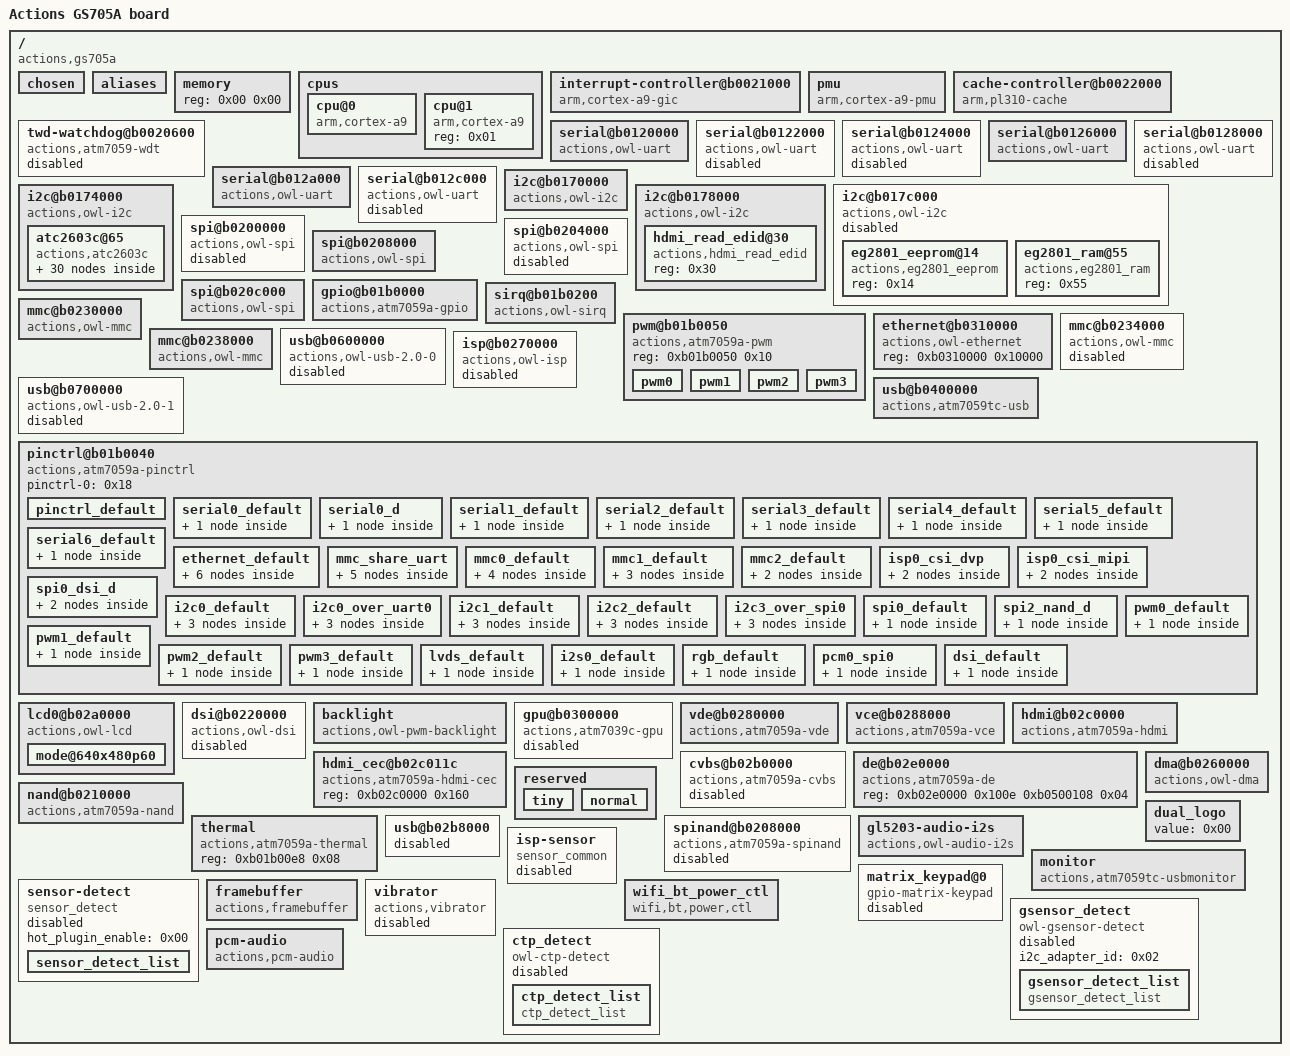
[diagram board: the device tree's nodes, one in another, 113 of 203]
/dts-v1/;

/ {
	#address-cells = < 0x01 >;
	#size-cells = < 0x01 >;
	compatible = "actions,gs705a\0actions,atm7059a";
	interrupt-parent = < 0x01 >;
	model = "Actions GS705A board";

	chosen {
		bootargs = "earlyprintk clk_ignore_unused selinux=0";
	};

	aliases {
		serial0 = "/serial@b0120000";
		serial1 = "/serial@b0122000";
		serial2 = "/serial@b0124000";
		serial3 = "/serial@b0126000";
		serial4 = "/serial@b0128000";
		serial5 = "/serial@b012a000";
		serial6 = "/serial@b012c000";
		i2c0 = "/i2c@b0170000";
		i2c1 = "/i2c@b0174000";
		i2c2 = "/i2c@b0178000";
		i2c3 = "/i2c@b017c000";
		spi0 = "/spi@b0200000";
		spi1 = "/spi@b0204000";
		spi2 = "/spi@b0208000";
		spi3 = "/spi@b020c000";
		dcdc1 = "/i2c@b0174000/atc2603c@65/dcdc1";
		dcdc2 = "/i2c@b0174000/atc2603c@65/dcdc2";
		dcdc3 = "/i2c@b0174000/atc2603c@65/dcdc3";
		dcdc4 = "/i2c@b0174000/atc2603c@65/dcdc4";
		ldo1 = "/i2c@b0174000/atc2603c@65/ldo1";
		ldo2 = "/i2c@b0174000/atc2603c@65/ldo2";
		ldo3 = "/i2c@b0174000/atc2603c@65/ldo3";
		ldo4 = "/i2c@b0174000/atc2603c@65/ldo4";
		ldo5 = "/i2c@b0174000/atc2603c@65/ldo5";
		ldo6 = "/i2c@b0174000/atc2603c@65/ldo6";
		ldo7 = "/i2c@b0174000/atc2603c@65/ldo7";
		ldo8 = "/i2c@b0174000/atc2603c@65/ldo8";
		ldo9 = "/i2c@b0174000/atc2603c@65/ldo9";
		ldo10 = "/i2c@b0174000/atc2603c@65/ldo10";
		ldo11 = "/i2c@b0174000/atc2603c@65/ldo11";
		switch1 = "/i2c@b0174000/atc2603c@65/switch1";
		switch2 = "/i2c@b0174000/atc2603c@65/switch2";
		isp0 = "/isp@b0270000";
		sdboot = "/mmc@b0230000";
		mmc0 = "/mmc@b0230000";
		mmc1 = "/mmc@b0234000";
		mmc2 = "/mmc@b0238000";
		usb0 = "/usb@b0600000";
		usb1 = "/usb@b0700000";
	};

	memory {
		device_type = "memory";
		reg = < 0x00 0x00 >;
	};

	cpus {
		#size-cells = < 0x00 >;
		#address-cells = < 0x01 >;

		cpu@0 {
			device_type = "cpu";
			compatible = "arm,cortex-a9";
			reg = < 0x00 >;
			transition-latency = < 0xee6c >;
			cpuvdd-supply = < 0x02 >;
		};

		cpu@1 {
			device_type = "cpu";
			compatible = "arm,cortex-a9";
			reg = < 0x01 >;
		};
	};

	interrupt-controller@b0021000 {
		compatible = "arm,cortex-a9-gic";
		interrupt-controller;
		#interrupt-cells = < 0x03 >;
		reg = < 0xb0021000 0x1000 0xb0020100 0x100 >;
		linux,phandle = < 0x01 >;
		phandle = < 0x01 >;
	};

	pmu {
		compatible = "arm,cortex-a9-pmu";
		interrupts = < 0x00 0x04 0x04 0x00 0x05 0x04 0x00 0x06 0x04 0x00 0x07 0x04 >;
	};

	cache-controller@b0022000 {
		compatible = "arm,pl310-cache";
		reg = < 0xb0022000 0x1000 >;
		cache-unified;
		cache-level = < 0x02 >;
		interrupts = < 0x00 0x37 0x04 >;
		arm,tag-latency = < 0x03 0x03 0x02 >;
		arm,data-latency = < 0x05 0x03 0x03 >;
	};

	twd-watchdog@b0020600 {
		compatible = "actions,atm7059-wdt";
		reg = < 0xb0020600 0x100 0xb0160000 0x20 >;
		interrupts = < 0x01 0x0e 0xf01 >;
		wd_type = "soft";
		status = "disabled";
	};

	serial@b0120000 {
		compatible = "actions,owl-uart\0actions,owl-uart-irc";
		reg = < 0xb0120000 0x2000 >;
		interrupts = < 0x00 0x1d 0x04 >;
		clock-frequency = < 0x2dc6c00 >;
		pinctrl-names = "default";
		pinctrl-0 = < 0x03 >;
		status = "okay";
	};

	serial@b0122000 {
		compatible = "actions,owl-uart";
		reg = < 0xb0122000 0x2000 >;
		interrupts = < 0x00 0x1e 0x04 >;
		clock-frequency = < 0x2dc6c00 >;
		pinctrl-names = "default";
		pinctrl-0 = < 0x04 >;
		status = "disabled";
	};

	serial@b0124000 {
		compatible = "actions,owl-uart";
		reg = < 0xb0124000 0x2000 >;
		interrupts = < 0x00 0x1f 0x04 >;
		clock-frequency = < 0x2dc6c00 >;
		pinctrl-names = "default";
		pinctrl-0 = < 0x05 >;
		status = "disabled";
	};

	serial@b0126000 {
		compatible = "actions,owl-uart";
		reg = < 0xb0126000 0x2000 >;
		interrupts = < 0x00 0x20 0x04 >;
		clock-frequency = < 0x2dc6c00 >;
		pinctrl-names = "default";
		pinctrl-0 = < 0x06 >;
		status = "okay";
	};

	serial@b0128000 {
		compatible = "actions,owl-uart";
		reg = < 0xb0128000 0x2000 >;
		interrupts = < 0x00 0x21 0x04 >;
		clock-frequency = < 0x2dc6c00 >;
		pinctrl-names = "default";
		pinctrl-0 = < 0x07 >;
		status = "disabled";
	};

	serial@b012a000 {
		compatible = "actions,owl-uart";
		reg = < 0xb012a000 0x2000 >;
		interrupts = < 0x00 0x22 0x04 >;
		clock-frequency = < 0x2dc6c00 >;
		status = "okay";
	};

	serial@b012c000 {
		compatible = "actions,owl-uart";
		reg = < 0xb012c000 0x2000 >;
		interrupts = < 0x00 0x23 0x04 >;
		clock-frequency = < 0x2dc6c00 >;
		pinctrl-names = "default";
		pinctrl-0 = < 0x08 >;
		status = "disabled";
	};

	i2c@b0170000 {
		#address-cells = < 0x01 >;
		#size-cells = < 0x00 >;
		compatible = "actions,owl-i2c";
		reg = < 0xb0170000 0x4000 >;
		interrupts = < 0x00 0x19 0x04 >;
	};

	i2c@b0174000 {
		#address-cells = < 0x01 >;
		#size-cells = < 0x00 >;
		compatible = "actions,owl-i2c";
		reg = < 0xb0174000 0x4000 >;
		interrupts = < 0x00 0x1a 0x04 >;
		i2c_num = < 0x01 >;
		clock-frequency = < 0x61a80 >;
		status = "okay";
		pinctrl-names = "default";
		pinctrl-0 = < 0x09 >;

		atc2603c@65 {
			compatible = "actions,atc2603c";
			reg = < 0x65 >;
			interrupt-parent = < 0x0a >;
			interrupts = < 0x02 0x04 >;
			interrupt-controller;
			#interrupt-cells = < 0x01 >;
			losc_32k_output_enable = < 0x01 >;
			losc_32k_output_voltage = < 0x1f >;

			pm {
				compatible = "actions,atc2603c-pm";
			};

			onoff {
				compatible = "actions,atc2603c-onoff";
			};

			atc260x-pwm {
				compatible = "actions,atc2603c-pwm";
			};

			rtc {
				compatible = "actions,atc2603c-rtc";
			};

			atc260x_gpio {
				compatible = "actions,atc2603c-gpio";
				gpio-controller;
				#gpio-cells = < 0x02 >;
			};

			atc260x_sgpio {
				compatible = "actions,atc2603c-sgpio";
				gpio-controller;
				#gpio-cells = < 0x02 >;
				interrupt-controller;
				#interrupt-cells = < 0x02 >;
				linux,phandle = < 0x1f >;
				phandle = < 0x1f >;
			};

			atc260x-adckeypad {
				keymapsize = < 0x04 >;
				filter_dep = < 0x03 >;
				variance = < 0x0a >;
				poll_interval = < 0x0a >;
				left_adc_val = < 0x00 0x5a 0xaf 0x10e >;
				right_adc_val = < 0x1e 0x78 0xdc 0x140 >;
				key_val = < 0x66 0x8b 0x73 0x72 >;
				adc_channel_name = "AUX0";
				compatible = "actions,atc2603c-adckeypad";
				status = "disabled";
			};

			atc260x-audio {
				compatible = "actions,atc2603c-audio";
				status = "okay";
				pinctrl-names = "default";
				pinctrl-0 = < 0x0b >;
				earphone_detect_gpios = < 0x0c 0x1c 0x00 >;
				speaker_en_gpios = < 0x0c 0x28 0x01 >;
				earphone_output_mode = < 0x01 >;
				mic_num = < 0x01 >;
				mic0_gain = < 0x07 0x07 >;
				speaker_gain = < 0xb4 0xb4 >;
				earphone_gain = < 0xbe 0xbe >;
				mic_mode = < 0x01 >;
				earphone_detect_method = < 0x03 >;
			};

			atc260x-hwmon {
				compatible = "actions,atc2603c-hwmon";
			};

			atc260x-power {
				compatible = "actions,atc2603c-power";
				bl_on_usb_pc_max_charge_current = < 0x64 >;
				bl_off_usb_pc_max_charge_current = < 0x1f4 >;
				bl_on_usb_adp_max_charge_current = < 0x3e8 >;
				bl_off_usb_adp_max_charge_current = < 0x4b0 >;
				bl_on_wall_adp_max_charge_current = < 0x3e8 >;
				bl_off_wall_adp_max_charge_current = < 0x4b0 >;
				bl_on_voltage_diff = < 0x15e >;
				bl_off_voltage_diff = < 0x190 >;
				support_adaptor_type = < 0x01 >;
				usb_adapter_as_ac = < 0x00 >;
				boot_cap_threshold = < 0x03 >;
				ext_dcdc_exist = < 0x00 >;
				pwms = < 0x0d 0x02 0x7a120 0x01 >;
				pwm-names = "ext_moto";
				ext_charger_exist = < 0x00 >;
				charger_led_exist = < 0x01 >;
				inner_charger_led_ctl = < 0x0c 0x16 0x00 >;
				low_power_led_ctl = < 0x0c 0x15 0x01 >;
				work_led_ctl = < 0x0c 0x12 0x01 >;
				myotg_id = < 0x0c 0x6a 0x00 >;
				otg_1_ctl = < 0x0c 0x17 0x00 >;
				otg_2_ctl = < 0x0c 0x5f 0x00 >;
				no_screen = < 0x01 >;
				temp_ctl_enable = < 0x00 >;
				temp_shutdown_low = < 0x3ed >;
				temp_stop_low = < 0x00 >;
				temp_shutdown_high = < 0x32 >;
				temp_stop_high = < 0x2d >;
				temp_diff_restart = < 0x02 >;
			};

			atc260x-cap-gauge {
				compatible = "actions,atc2603c-cap-gauge";
				capacity = < 0x834 >;
				icm_available = < 0x01 >;
				icm_ohm_val = < 0x14 >;
				taper_voltage = < 0x1068 >;
				taper_current = < 0x12c >;
				min_over_chg_protect_voltage = < 0x10b3 >;
				ch_resistor = < 0x78 >;
				disch_resistor = < 0xb4 >;
				terminal_voltage = < 0xd7a >;
				suspend_current = < 0x578 >;
				shutdown_current = < 0x32 >;
				print_switch = < 0x00 >;
				log_switch = < 0x00 >;
				ocv_soc_00 = < 0xd95 0xdce 0xe07 0xe28 0xe35 0xe41 0xe4d 0xe53 0xe59 0xe5d >;
				ocv_soc_10 = < 0xe62 0xe65 0xe6a 0xe6d 0xe74 0xe7a 0xe80 0xe84 0xe8a 0xe90 >;
				ocv_soc_20 = < 0xe94 0xe98 0xe9b 0xea0 0xea3 0xea7 0xeab 0xeae 0xeb1 0xeb5 >;
				ocv_soc_30 = < 0xeb8 0xebb 0xebf 0xec1 0xec6 0xec8 0xecc 0xecf 0xed1 0xed2 >;
				ocv_soc_40 = < 0xed8 0xed9 0xedc 0xedf 0xee4 0xee7 0xeeb 0xeef 0xef1 0xef6 >;
				ocv_soc_50 = < 0xefa 0xefe 0xf01 0xf05 0xf0a 0xf0e 0xf12 0xf18 0xf1e 0xf22 >;
				ocv_soc_60 = < 0xf28 0xf31 0xf37 0xf3e 0xf44 0xf4c 0xf56 0xf5d 0xf64 0xf6b >;
				ocv_soc_70 = < 0xf72 0xf79 0xf80 0xf84 0xf8b 0xf91 0xf98 0xf9d 0xfa5 0xfac >;
				ocv_soc_80 = < 0xfb3 0xfbc 0xfc4 0xfce 0xfd6 0xfdd 0xfe4 0xfeb 0xff4 0xffa >;
				ocv_soc_90 = < 0x1003 0x100b 0x1013 0x101e 0x1024 0x102d 0x1038 0x1040 0x104a 0x1054 >;
			};

			atc260x-backup {
				compatible = "actions,atc2603c-backup";
				status = "disabled";
			};

			dcdc1 {
				compatible = "actions,atc2603c-dcdc1\0actions,atc2603c-dcdc";
				regulator-name = "dcdc1";
				regulator-min-microvolt = < 0xaae60 >;
				regulator-max-microvolt = < 0x155cc0 >;
				regulator-always-on;
				linux,phandle = < 0x02 >;
				phandle = < 0x02 >;
			};

			dcdc2 {
				compatible = "actions,atc2603c-dcdc2\0actions,atc2603c-dcdc";
				regulator-name = "dcdc2";
				regulator-min-microvolt = < 0x13d620 >;
				regulator-max-microvolt = < 0x2191c0 >;
				regulator-always-on;
			};

			dcdc3 {
				compatible = "actions,atc2603c-dcdc3\0actions,atc2603c-dcdc";
				regulator-name = "dcdc3";
				regulator-min-microvolt = < 0x27ac40 >;
				regulator-max-microvolt = < 0x325aa0 >;
				regulator-always-on;
			};

			dcdc4 {
				status = "disabled";
			};

			dcdc5 {
				status = "disabled";
			};

			ldo1 {
				compatible = "actions,atc2603c-ldo1\0actions,atc2603c-ldo";
				regulator-name = "ldo1";
				regulator-min-microvolt = < 0x2ab980 >;
				regulator-max-microvolt = < 0x2ab980 >;
				regulator-always-on;
			};

			ldo2 {
				compatible = "actions,atc2603c-ldo2\0actions,atc2603c-ldo";
				regulator-name = "ldo2";
				regulator-min-microvolt = < 0x27ac40 >;
				regulator-max-microvolt = < 0x325aa0 >;
				regulator-always-on;
			};

			ldo3 {
				compatible = "actions,atc2603c-ldo3\0actions,atc2603c-ldo";
				regulator-name = "ldo3";
				regulator-min-microvolt = < 0x16e360 >;
				regulator-max-microvolt = < 0x1e8480 >;
				regulator-always-on;
			};

			ldo4 {
				status = "disabled";
			};

			ldo5 {
				compatible = "actions,atc2603c-ldo5\0actions,atc2603c-ldo";
				regulator-name = "ldo5";
				regulator-min-microvolt = < 0x2f4d60 >;
				regulator-max-microvolt = < 0x325aa0 >;
				regulator-suspend-off;
			};

			ldo6 {
				compatible = "actions,atc2603c-ldo6\0actions,atc2603c-ldo";
				regulator-name = "ldo6";
				regulator-min-microvolt = < 0xaae60 >;
				regulator-max-microvolt = < 0x155cc0 >;
				regulator-always-on;
			};

			ldo7 {
				compatible = "actions,atc2603c-ldo7\0actions,atc2603c-ldo";
				regulator-name = "ldo7";
				regulator-min-microvolt = < 0x1b7740 >;
				regulator-max-microvolt = < 0x1b7740 >;
				regulator-suspend-off;
			};

			ldo8 {
				compatible = "actions,atc2603c-ldo8\0actions,atc2603c-ldo";
				regulator-name = "ldo8";
				regulator-min-microvolt = < 0x231860 >;
				regulator-max-microvolt = < 0x325aa0 >;
			};

			ldo9 {
				status = "disabled";
			};

			ldo10 {
				status = "disabled";
			};

			ldo11 {
				compatible = "actions,atc2603c-ldo11\0actions,atc2603c-ldo";
				regulator-name = "ldo11";
				regulator-min-microvolt = < 0x27ac40 >;
				regulator-max-microvolt = < 0x325aa0 >;
				regulator-always-on;
			};

			switch1 {
				compatible = "actions,atc2603c-switch1\0actions,atc2603c-switch";
				regulator-name = "switch1";
				regulator-min-microvolt = < 0x2f4d60 >;
				regulator-max-microvolt = < 0x325aa0 >;
				regulator-always-on;
			};

			switch2 {
				status = "disabled";
			};
		};
	};

	i2c@b0178000 {
		#address-cells = < 0x01 >;
		#size-cells = < 0x00 >;
		compatible = "actions,owl-i2c";
		reg = < 0xb0178000 0x4000 >;
		interrupts = < 0x00 0x1b 0x04 >;
		i2c_num = < 0x02 >;
		clock-frequency = < 0x61a80 >;
		status = "okay";
		pinctrl-names = "default";
		pinctrl-0 = < 0x0e >;
		linux,phandle = < 0x1d >;
		phandle = < 0x1d >;

		hdmi_read_edid@30 {
			compatible = "actions,hdmi_read_edid";
			reg = < 0x30 >;
		};
	};

	i2c@b017c000 {
		#address-cells = < 0x01 >;
		#size-cells = < 0x00 >;
		compatible = "actions,owl-i2c";
		reg = < 0xb017c000 0x4000 >;
		interrupts = < 0x00 0x1c 0x04 >;
		i2c_num = < 0x03 >;
		clock-frequency = < 0x61a80 >;
		status = "disabled";
		pinctrl-names = "default";
		pinctrl-0 = < 0x0f >;

		eg2801_eeprom@14 {
			compatible = "actions,eg2801_eeprom";
			reg = < 0x14 >;
		};

		eg2801_ram@55 {
			compatible = "actions,eg2801_ram";
			reg = < 0x55 >;
		};
	};

	spi@b0200000 {
		#address-cells = < 0x01 >;
		#size-cells = < 0x00 >;
		compatible = "actions,owl-spi";
		reg = < 0xb0200000 0x4000 >;
		interrupts = < 0x00 0x13 0x04 >;
		status = "disabled";
	};

	spi@b0204000 {
		#address-cells = < 0x01 >;
		#size-cells = < 0x00 >;
		compatible = "actions,owl-spi";
		reg = < 0xb0204000 0x4000 >;
		interrupts = < 0x00 0x14 0x04 >;
		status = "disabled";
	};

	spi@b0208000 {
		#address-cells = < 0x01 >;
		#size-cells = < 0x00 >;
		compatible = "actions,owl-spi";
		reg = < 0xb0208000 0x4000 >;
		interrupts = < 0x00 0x15 0x04 >;
	};

	spi@b020c000 {
		#address-cells = < 0x01 >;
		#size-cells = < 0x00 >;
		compatible = "actions,owl-spi";
		reg = < 0xb020c000 0x4000 >;
		interrupts = < 0x00 0x16 0x04 >;
	};

	gpio@b01b0000 {
		compatible = "actions,atm7059a-gpio";
		reg = < 0xb01b0000 0x40 >;
		interrupts = < 0x00 0x24 0x04 0x00 0x25 0x04 0x00 0x26 0x04 0x00 0x27 0x04 0x00 0x28 0x04 >;
		#gpio-cells = < 0x02 >;
		gpio-controller;
		#interrupt-cells = < 0x02 >;
		interrupt-controller;
		status = "okay";
		linux,phandle = < 0x0c >;
		phandle = < 0x0c >;
	};

	sirq@b01b0200 {
		compatible = "actions,owl-sirq";
		reg = < 0xb01b0200 0x04 >;
		interrupts = < 0x00 0x0d 0x04 0x00 0x0e 0x04 0x00 0x0f 0x04 >;
		#interrupt-cells = < 0x02 >;
		interrupt-controller;
		linux,phandle = < 0x0a >;
		phandle = < 0x0a >;
	};

	pwm@b01b0050 {
		compatible = "actions,atm7059a-pwm";
		reg = < 0xb01b0050 0x10 >;
		#pwm-cells = < 0x03 >;
		linux,phandle = < 0x0d >;
		phandle = < 0x0d >;

		pwm0 {
			id = < 0x00 >;
			pinctrl-names = "default";
			pinctrl-0 = < 0x10 >;
		};

		pwm1 {
			id = < 0x01 >;
			pinctrl-names = "default";
			pinctrl-0 = < 0x11 >;
		};

		pwm2 {
			id = < 0x02 >;
			pinctrl-names = "default";
			pinctrl-0 = < 0x12 >;
		};

		pwm3 {
			id = < 0x03 >;
			pinctrl-names = "default";
			pinctrl-0 = < 0x13 >;
		};
	};

	ethernet@b0310000 {
		#address-cells = < 0x01 >;
		#size-cells = < 0x00 >;
		compatible = "actions,owl-ethernet";
		reg = < 0xb0310000 0x10000 >;
	};

	mmc@b0230000 {
		#address-cells = < 0x01 >;
		#size-cells = < 0x00 >;
		compatible = "actions,owl-mmc";
		reg = < 0xb0230000 0x38 >;
		pinctrl-names = "default\0share_uart2_5";
		pinctrl-0 = < 0x14 >;
		pinctrl-1 = < 0x15 >;
		max_clk = < 0x17d7840 >;
		card_type = "memory";
		card_detect_mode = "gpio";
		card_detect_gpios = < 0x0c 0x29 0x00 >;
		interrupts = < 0x00 0x2a 0x04 >;
		status = "okay";
		sd_vcc = "switch1";
		sdio3_0_not_supported;
	};

	mmc@b0234000 {
		#address-cells = < 0x01 >;
		#size-cells = < 0x00 >;
		compatible = "actions,owl-mmc";
		reg = < 0xb0234000 0x38 >;
		interrupts = < 0x00 0x2b 0x04 >;
		pinctrl-names = "default";
		pinctrl-0 = < 0x16 >;
		card_type = "wifi";
		status = "disabled";
	};

	mmc@b0238000 {
		#address-cells = < 0x01 >;
		#size-cells = < 0x00 >;
		compatible = "actions,owl-mmc";
		reg = < 0xb0238000 0x38 >;
		interrupts = < 0x00 0x2c 0x04 >;
		pinctrl-names = "default";
		pinctrl-0 = < 0x17 >;
		card_type = "memory";
		card_detect_mode = "command";
		status = "okay";
	};

	usb@b0600000 {
		#address-cells = < 0x01 >;
		#size-cells = < 0x00 >;
		compatible = "actions,owl-usb-2.0-0";
		reg = < 0xb0600000 0x1000 >;
		interrupts = < 0x00 0x18 0x04 >;
		status = "disabled";
		port0_host_plug_detect = < 0x03 >;
	};

	usb@b0700000 {
		#address-cells = < 0x01 >;
		#size-cells = < 0x00 >;
		compatible = "actions,owl-usb-2.0-1";
		reg = < 0xb0700000 0x1000 >;
		interrupts = < 0x00 0x3d 0x04 >;
		status = "disabled";
		port1_host_plug_detect = < 0x03 >;
	};

	usb@b0400000 {
		#address-cells = < 0x01 >;
		#size-cells = < 0x00 >;
		compatible = "actions,atm7059tc-usb";
		reg = < 0xb0400000 0xcd00 0xb040cd00 0x59 >;
		interrupts = < 0x00 0x17 0x04 >;
		usb_serialnumber_config = < 0x01 >;
		usb_hs_output_strength = < 0x02 >;
		status = "okay";
	};

	isp@b0270000 {
		#address-cells = < 0x01 >;
		#size-cells = < 0x01 >;
		compatible = "actions,owl-isp";
		reg = < 0xb0270000 0x400 0xb0160020 0x04 >;
		interrupts = < 0x00 0x0c 0x04 >;
		avdd-src = "regulator";
		avdd-regulator = "ldo1";
		avdd-regulator-scope = < 0x2ab980 0x2ae090 >;
		dvdd-gpios = < 0x0c 0x39 0x00 >;
		sensors = "rear";
		pwdn-rear-gpios = < 0x0c 0x49 0x00 >;
		pwdn-front-gpios = < 0x0c 0x46 0x00 >;
		rear-reset-gpios = < 0x0c 0x72 0x01 >;
		status = "disabled";
		linux,phandle = < 0x1c >;
		phandle = < 0x1c >;
	};

	pinctrl@b01b0040 {
		compatible = "actions,atm7059a-pinctrl";
		pinctrl-names = "default";
		pinctrl-0 = < 0x18 >;

		pinctrl_default {
			linux,phandle = < 0x18 >;
			phandle = < 0x18 >;
		};

		serial0_default {

			serial_0 {
				actions,groups = "mfp2_2_0\0mfp3_21_19";
				actions,function = "uart0";
			};
		};

		serial0_d {
			linux,phandle = < 0x03 >;
			phandle = < 0x03 >;

			serial_d {
				actions,groups = "mfp2_22\0mfp2_23";
				actions,function = "uart0";
			};
		};

		serial1_default {
			linux,phandle = < 0x04 >;
			phandle = < 0x04 >;

			serial_1 {
				actions,groups = "mfp2_13_11";
				actions,function = "uart1";
			};
		};

		serial2_default {
			linux,phandle = < 0x05 >;
			phandle = < 0x05 >;

			serial_2 {
				actions,groups = "mfp2_23\0mfp2_22\0uart2_dummy";
				actions,function = "uart2";
			};
		};

		serial3_default {
			linux,phandle = < 0x06 >;
			phandle = < 0x06 >;

			serial_3 {
				actions,groups = "mfp2_21\0mfp2_20\0uart3_dummy";
				actions,function = "uart3";
			};
		};

		serial4_default {
			linux,phandle = < 0x07 >;
			phandle = < 0x07 >;

			serial_4 {
				actions,groups = "uart4_dummy";
				actions,function = "uart4";
			};
		};

		serial5_default {

			serial_5 {
				actions,groups = "mfp2_19_17\0mfp2_16_14";
				actions,function = "uart5";
			};
		};

		serial6_default {
			linux,phandle = < 0x08 >;
			phandle = < 0x08 >;

			serial_6 {
				actions,groups = "mfp0_18_16_eth_txd0\0mfp0_18_16_eth_txd1";
				actions,function = "uart6";
			};
		};

		ethernet_default {

			ethernet_smi {
				actions,groups = "eth_smi_dummy";
				actions,function = "eth_rmii";
			};

			ethernet_rmii_txd01 {
				actions,groups = "mfp0_18_16_eth_txd0\0mfp0_18_16_eth_txd1";
				actions,function = "eth_rmii";
			};

			ethernet_rmii_txen_rxer {
				actions,groups = "mfp0_15_13_rmii_txen\0mfp0_15_13_rmii_rxen";
				actions,function = "eth_rmii";
			};

			ethernet_rmii_crs_dv {
				actions,groups = "mfp0_22_20";
				actions,function = "eth_rmii";
			};

			ethernet_rmii_rxd10 {
				actions,groups = "mfp0_10_8_rmii_rxd1\0mfp0_10_8_rmii_rxd0";
				actions,function = "eth_rmii";
			};

			ethernet_rmii_ref_clk {
				actions,groups = "mfp0_7_6";
				actions,function = "eth_rmii";
			};
		};

		mmc_share_uart {
			linux,phandle = < 0x15 >;
			phandle = < 0x15 >;

			sd0_mfp_cmd_clk {
				actions,groups = "mfp2_8_7\0mfp2_6_5";
				actions,function = "sd0";
			};

			sd0_pull_d0_d3_cmd {
				actions,pins = "P_SD0_CMD";
				actions,pull = < 0x02 >;
			};

			sd0_pull_clk {
				actions,pins = "P_SD0_CLK";
				actions,pull = < 0x00 >;
			};

			sd0_d0_d3_cmd_clk_paddrv {
				actions,groups = "paddrv1_19_18\0paddrv1_17_16";
				actions,paddrv = < 0x01 >;
			};

			serial_5 {
				actions,groups = "mfp2_19_17\0mfp2_16_14";
				actions,function = "uart5";
			};
		};

		mmc0_default {
			linux,phandle = < 0x14 >;
			phandle = < 0x14 >;

			sd0_mfp_d0_d3_cmd_clk {
				actions,groups = "mfp2_19_17\0mfp2_16_14\0mfp2_13_11\0mfp2_8_7\0mfp2_6_5";
				actions,function = "sd0";
			};

			sd0_pull_d0_d3_cmd {
				actions,pins = "P_SD0_D0\0P_SD0_D1\0P_SD0_D2\0P_SD0_D3\0P_SD0_CMD";
				actions,pull = < 0x02 >;
			};

			sd0_pull_clk {
				actions,pins = "P_SD0_CLK";
				actions,pull = < 0x00 >;
			};

			sd0_d0_d3_cmd_clk_paddrv {
				actions,groups = "paddrv1_23_22\0paddrv1_19_18\0paddrv1_17_16";
				actions,paddrv = < 0x01 >;
			};
		};

		mmc1_default {
			linux,phandle = < 0x16 >;
			phandle = < 0x16 >;

			sd1_mfp_d0_d3_cmd_clk {
				actions,groups = "mfp2_10_9\0mfp2_4_3\0sd1_dummy";
				actions,function = "sd1";
			};

			sd1_pull_d0_d3_cmd {
				actions,pins = "P_SD1_D0\0P_SD1_D1\0P_SD1_D2\0P_SD1_D3\0P_SD1_CMD";
				actions,pull = < 0x02 >;
			};

			sd1_d0_d3_cmd_clk_paddrv {
				actions,groups = "paddrv1_21_20\0paddrv1_15_14\0paddrv1_13_12";
				actions,paddrv = < 0x01 >;
			};
		};

		mmc2_default {
			linux,phandle = < 0x17 >;
			phandle = < 0x17 >;

			sd2_mfp_d0_d3_cmd_clk {
				actions,groups = "mfp3_3";
				actions,function = "sd2";
			};

			sd2_pull_d0_d3_cmd {
				actions,pins = "P_DNAND_D0\0P_DNAND_D1\0P_DNAND_D2\0P_DNAND_D3\0P_DNAND_D4\0P_DNAND_D5\0P_DNAND_D6\0P_DNAND_D7\0P_DNAND_RDBN";
				actions,pull = < 0x02 >;
			};
		};

		isp0_csi_dvp {
			linux,phandle = < 0x1e >;
			phandle = < 0x1e >;

			isp0_csi_dvp_mfp {
				actions,groups = "mfp3_29_28\0mfp3_23_22\0mfp3_15_14\0mfp3_13_12";
				actions,function = "sens0";
			};

			sens0_clk_out_pdrv {
				actions,groups = "paddrv2_13_12";
				actions,paddrv = < 0x00 >;
			};
		};

		isp0_csi_mipi {

			isp0_csi_mipi_mfp {
				actions,groups = "mfp3_29_28\0mfp3_15_14";
				actions,function = "mipi_csi";
			};

			isp0_csi_mipi_clkout_mfp {
				actions,groups = "mfp3_23_22";
				actions,function = "sens0";
			};
		};

		spi0_dsi_d {

			spi0_mfp {
				actions,groups = "mfp1_9_7\0mfp1_20_19\0mfp1_18_17\0mfp2_26_24";
				actions,function = "spi0";
			};

			spi0_paddrv {
				actions,groups = "paddrv1_25_24";
				actions,paddrv = < 0x02 >;
			};
		};

		i2c0_default {

			i2c0_default_mfp {
				actions,groups = "mfp3_18_16";
				actions,function = "i2c0";
			};

			i2c0_default_paddrv {
				actions,groups = "paddrv2_24_23";
				actions,paddrv = < 0x00 >;
			};

			i2c0_default_pull_up {
				actions,pins = "P_I2C0_SCLK\0P_I2C0_SDATA";
				actions,pull = < 0x02 >;
			};
		};

		i2c0_over_uart0 {

			i2c0_over_uart0_mfp {
				actions,groups = "mfp2_2_0\0mfp3_21_19";
				actions,function = "i2c0";
			};

			i2c0_over_uart0_paddrv {
				actions,groups = "paddrv2_31_30\0paddrv2_29_28";
				actions,paddrv = < 0x00 >;
			};

			i2c0_over_uart0_pull_up {
				actions,pins = "P_UART0_RX\0P_UART0_TX";
				actions,pull = < 0x02 >;
			};
		};

		i2c1_default {
			linux,phandle = < 0x09 >;
			phandle = < 0x09 >;

			i2c1_default_mfp {
				actions,groups = "i2c1_dummy";
				actions,function = "i2c1";
			};

			i2c1_default_paddrv {
				actions,groups = "paddrv2_22_21";
				actions,paddrv = < 0x00 >;
			};

			i2c1_default_pull_up {
				actions,pins = "P_I2C1_SCLK\0P_I2C1_SDATA";
				actions,pull = < 0x00 >;
			};
		};

		i2c2_default {
			linux,phandle = < 0x0e >;
			phandle = < 0x0e >;

			i2c2_default_mfp {
				actions,groups = "i2c2_dummy";
				actions,function = "i2c2";
			};

			i2c2_default_paddrv {
				actions,groups = "paddrv2_22_21";
				actions,paddrv = < 0x00 >;
			};

			i2c2_default_pull_up {
				actions,pins = "P_I2C2_SCLK\0P_I2C2_SDATA";
				actions,pull = < 0x02 >;
			};
		};

		i2c3_over_spi0 {
			linux,phandle = < 0x0f >;
			phandle = < 0x0f >;

			i2c3_over_spi0_mfp {
				actions,groups = "mfp1_4_3";
				actions,function = "i2c3";
			};

			i2c3_over_spi0_paddrv {
				actions,groups = "paddrv1_11_10";
				actions,paddrv = < 0x01 >;
			};

			i2c3_over_spi0_pull_up {
				actions,pins = "P_SPI0_SCLK\0P_SPI0_MOSI";
				actions,pull = < 0x00 >;
			};
		};

		spi0_default {

			spi0_mfp {
				actions,groups = "mfp1_2_0\0mfp1_4_3";
				actions,function = "spi0";
			};
		};

		spi2_nand_d {
			linux,phandle = < 0x1b >;
			phandle = < 0x1b >;

			spi2_mfp {
				actions,groups = "mfp3_2";
				actions,function = "spi2";
			};
		};

		pwm0_default {
			linux,phandle = < 0x10 >;
			phandle = < 0x10 >;

			pwm0_mfp {
				actions,groups = "mfp1_31_29_ks_in2";
				actions,function = "pwm0";
			};
		};

		pwm1_default {
			linux,phandle = < 0x11 >;
			phandle = < 0x11 >;

			pwm1_mfp {
				actions,groups = "mfp1_28_26_ks_in3";
				actions,function = "pwm1";
			};
		};

		pwm2_default {
			linux,phandle = < 0x12 >;
			phandle = < 0x12 >;

			pwm2_mfp {
				actions,groups = "mfp1_28_26_ks_out0";
				actions,function = "pwm2";
			};
		};

		pwm3_default {
			linux,phandle = < 0x13 >;
			phandle = < 0x13 >;

			pwm3_mfp {
				actions,groups = "mfp1_28_26_ks_out1";
				actions,function = "pwm3";
			};
		};

		lvds_default {

			lvds_mux {
				actions,groups = "mfp1_22_21\0mfp1_6_5\0mfp2_28_27";
				actions,function = "lvds";
			};
		};

		i2s0_default {
			linux,phandle = < 0x0b >;
			phandle = < 0x0b >;

			i2s0_default_mfp {
				actions,groups = "mfp0_2_1_i2s0\0mfp0_4_3\0mfp0_5";
				actions,function = "i2s0";
			};
		};

		rgb_default {
			linux,phandle = < 0x19 >;
			phandle = < 0x19 >;

			rgb_mux {
				actions,groups = "mfp0_25_23\0mfp1_16_14\0mfp1_22_21\0mfp1_13_12\0mfp1_11_10\0mfp1_6_5\0mfp2_30_29\0mfp2_28_27";
				actions,function = "lcd0";
			};
		};

		pcm0_spi0 {

			pcm0_spi0_mfp {
				actions,groups = "mfp1_2_0\0mfp1_4_3";
				actions,function = "pcm0";
			};
		};

		dsi_default {

			dsi_mux {
				actions,groups = "mfp1_20_19\0mfp1_18_17\0mfp1_13_12\0mfp1_11_10\0mfp1_9_7\0mfp2_30_29";
				actions,function = "dsi";
			};
		};
	};

	lcd0@b02a0000 {
		compatible = "actions,owl-lcd";
		reg = < 0xb02a0000 0x20c >;
		interrupts = < 0x00 0x2d 0x04 >;
		status = "okay";
		pinctrl-names = "default";
		pinctrl-0 = < 0x19 >;
		lcd_power_gpios = < 0x0c 0x24 0x00 >;
		lcd_reset_gpios = < 0x0c 0x23 0x00 >;
		lcd_spics_gpios = < 0x0c 0x11 0x01 >;
		lcd_spiclk_gpios = < 0x0c 0x78 0x01 >;
		lcd_spidat_gpios = < 0x0c 0x79 0x01 >;
		port_type = "rgb";
		data_width = < 0x00 >;
		videomode-0 = < 0x1a >;
		vsync_inversion = < 0x01 >;
		hsync_inversion = < 0x01 >;
		dclk_inversion = < 0x01 >;
		lde_inversion = < 0x00 >;
		lightness = < 0x80 >;
		saturation = < 0x07 >;
		contrast = < 0x05 >;

		mode@640x480p60 {
			refresh = < 0x3c >;
			xres = < 0x280 >;
			yres = < 0x1e0 >;
			pixclock = < 0xb798 >;
			left_margin = < 0x10 >;
			right_margin = < 0x14 >;
			upper_margin = < 0x0f >;
			lower_margin = < 0x05 >;
			hsync_len = < 0x1e >;
			vsync_len = < 0x02 >;
			vmode = < 0x00 >;
			linux,phandle = < 0x1a >;
			phandle = < 0x1a >;
		};
	};

	dsi@b0220000 {
		compatible = "actions,owl-dsi";
		reg = < 0xb0220000 0x8c >;
		interrupts = < 0x00 0x33 0x04 >;
		status = "disabled";
	};

	backlight {
		compatible = "actions,owl-pwm-backlight";
		pwms = < 0x0d 0x00 0xc350 0x00 >;
		total_steps = < 0x400 >;
		min_brightness = < 0x00 >;
		max_brightness = < 0x400 >;
		dft_brightness = < 0x100 >;
		delay_bf_pwm = < 0xc8 >;
		delay_af_pwm = < 0x0a >;
	};

	gpu@b0300000 {
		compatible = "actions,atm7039c-gpu";
		reg = < 0xb0300000 0x10000 >;
		interrupts = < 0x00 0x03 0x04 >;
		normal_value = < 0x02 >;
		status = "disabled";
	};

	vde@b0280000 {
		compatible = "actions,atm7059a-vde";
		reg = < 0xb0280000 0x108 >;
		interrupts = < 0x00 0x32 0x04 >;
	};

	vce@b0288000 {
		compatible = "actions,atm7059a-vce";
		reg = < 0xb0288000 0x94 >;
		interrupts = < 0x00 0x31 0x04 >;
	};

	hdmi@b02c0000 {
		compatible = "actions,atm7059a-hdmi";
		reg = < 0xb02c0000 0x160 >;
		status = "okay";
		hdcp_onoff = < 0x00 >;
		channel_invert = < 0x00 >;
		bit_invert = < 0x00 >;
		hotplugable = < 0x01 >;
		bootable = < 0x01 >;
		i2cbus = < 0x02 >;
		bootrotate = < 0x00 >;
		default_resolution = "1280x720p-60";
	};

	hdmi_cec@b02c011c {
		compatible = "actions,atm7059a-hdmi-cec";
		reg = < 0xb02c0000 0x160 >;
	};

	cvbs@b02b0000 {
		compatible = "actions,atm7059a-cvbs";
		reg = < 0xb02b0000 0x80 >;
		default_mode = "PAL";
		status = "disabled";
	};

	de@b02e0000 {
		compatible = "actions,atm7059a-de";
		reg = < 0xb02e0000 0x100e 0xb0500108 0x04 >;
	};

	nand@b0210000 {
		#address-cells = < 0x01 >;
		#size-cells = < 0x01 >;
		compatible = "actions,atm7059a-nand";
		reg = < 0xb0210000 0xb4 0xb0160000 0xfc 0xb01b0000 0x90 0xb0260000 0xd00 >;
		interrupts = < 0x00 0x29 0x04 >;
	};

	dma@b0260000 {
		compatible = "actions,owl-dma";
		reg = < 0xb0260000 0xd00 >;
		interrupts = < 0x00 0x39 0x04 0x00 0x3a 0x04 0x00 0x3b 0x04 0x00 0x3c 0x04 >;
	};

	thermal {
		#address-cells = < 0x01 >;
		#size-cells = < 0x01 >;
		compatible = "actions,atm7059a-thermal";
		reg = < 0xb01b00e8 0x08 >;
	};

	reserved {

		tiny {
			fb_heap_size = < 0x09 >;
			kinfo_heap_size = < 0x01 >;
			carveout_heap_size = < 0x00 >;
			dma_heap_size = < 0x20 >;
		};

		normal {
			fb_heap_size = < 0x08 >;
			kinfo_heap_size = < 0x01 >;
			carveout_heap_size = < 0x40 >;
			dma_heap_size = < 0x80 >;
		};
	};

	dual_logo {
		value = < 0x00 >;
	};

	spinand@b0208000 {
		compatible = "actions,atm7059a-spinand";
		clock-frequency = < 0x2faf080 >;
		pinctrl-names = "default";
		pinctrl-0 = < 0x1b >;
		status = "disabled";
	};

	gl5203-audio-i2s {
		#address-cells = < 0x01 >;
		#size-cells = < 0x01 >;
		compatible = "actions,owl-audio-i2s";
		reg = < 0xb0100000 0x34 0xb0110000 0x8010 >;
		pcm = < 0x00 >;
	};

	usb@b02b8000 {
		vbus-src = "gpio";
		vbus-regulator = "LDO1";
		regulator-scope = < 0x325aa0 0x3567e0 >;
		status = "disabled";
	};

	monitor {
		compatible = "actions,atm7059tc-usbmonitor";
		detect_type = < 0x03 >;
		idpin_type = < 0x00 >;
		vbus_type = < 0x02 >;
		vbus_otg_en_gpios = < 0x0c 0x4e 0x00 >;
		status = "okay";
	};

	isp-sensor {
		compatible = "sensor_common";
		rear_bus_type = "dvp";
		front_bus_type = "dvp";
		rear_data_type = "yuv";
		front_data_type = "yuv";
		host = < 0x1c >;
		rear_channel = < 0x00 >;
		front_channel = < 0x00 >;
		i2c_adapter = < 0x1d >;
		pinctrl-names = "default";
		pinctrl-0 = < 0x1e >;
		status = "disabled";
	};

	sensor-detect {
		compatible = "sensor_detect";
		status = "disabled";
		hot_plugin_enable = < 0x00 >;

		sensor_detect_list {
			gc0308 = < 0x01 >;
			gc0328 = < 0x01 >;
			gc0329 = < 0x01 >;
			gc0312 = < 0x01 >;
			gc2035 = < 0x01 >;
			gc2145 = < 0x01 >;
			gc2155 = < 0x01 >;
			hi708 = < 0x01 >;
			hi257 = < 0x01 >;
			ov2686 = < 0x01 >;
			ov5640 = < 0x01 >;
			sp0718 = < 0x01 >;
			sp0a19 = < 0x01 >;
			sp2519 = < 0x01 >;
			siv121du = < 0x01 >;
			soc5140 = < 0x01 >;
		};
	};

	matrix_keypad@0 {
		compatible = "gpio-matrix-keypad";
		status = "disabled";
		debounce-delay-ms = < 0x14 >;
		col-scan-delay-us = < 0x0a >;
		row-gpios = < 0x0c 0x2d 0x00 0x0c 0x2e 0x00 >;
		col-gpios = < 0x0c 0x32 0x00 0x0c 0x33 0x00 0x0c 0x30 0x00 0x0c 0x2f 0x00 >;
		linux,keymap = < 0x8b 0x1009e 0x2009f 0x30069 0x1000080 0x1010077 0x1020078 0x1030079 >;
	};

	framebuffer {
		compatible = "actions,framebuffer";
		def_display = "lcd";
		xres = < 0x280 >;
		yres = < 0x1e0 >;
		bpp = < 0x04 >;
		mode = < 0x00 >;
	};

	vibrator {
		compatible = "actions,vibrator";
		status = "disabled";
	};

	wifi_bt_power_ctl {
		compatible = "wifi,bt,power,ctl";
		wifi_bt_power_gpios = < 0x1f 0x05 0x00 >;
		wifi_vol_range = < 0x325aa0 0x325aa0 >;
		wifi_en_gpios = < 0x0c 0x5a 0x00 >;
		bt_en_gpios = < 0x0c 0x5b 0x00 >;
		wifi_wakeup_host_gpios = < 0x0c 0x73 0x00 >;
	};

	gsensor_detect {
		compatible = "owl-gsensor-detect";
		status = "disabled";
		i2c_adapter_id = < 0x02 >;

		gsensor_detect_list {
			compatible = "gsensor_detect_list";
			afa750 = < 0x00 >;
			bma220 = < 0x00 >;
			bma222 = < 0x01 >;
			bma250 = < 0x00 >;
			dmard10 = < 0x00 >;
			kxtj9 = < 0x00 >;
			lis3dh = < 0x00 >;
			mc3210 = < 0x00 >;
			mc3230 = < 0x00 >;
			mc3232 = < 0x01 >;
			mc3236 = < 0x01 >;
			mma7660 = < 0x00 >;
			mma8452 = < 0x00 >;
			stk8312 = < 0x01 >;
			stk8313 = < 0x01 >;
		};
	};

	ctp_detect {
		compatible = "owl-ctp-detect";
		status = "disabled";
		i2c_adapter_id = < 0x01 >;
		tp_vcc = "ldo5";
		reset_gpios = < 0x0c 0x23 0x01 >;
		interrupt-parent = < 0x0a >;
		interrupts = < 0x00 0x04 >;
		vol_range = < 0x2f4d60 0x2f7470 >;

		ctp_detect_list {
			compatible = "ctp_detect_list";
			ICN83XX = < 0x00 >;
			GSLX6X0 = < 0x01 >;
			FT52-406 = < 0x00 >;
			FT5606 = < 0x00 >;
			GT813 = < 0x00 >;
			AW5206 = < 0x00 >;
			AW5209 = < 0x00 >;
			CT36X = < 0x00 >;
			HL3X06 = < 0x00 >;
			ILITEK = < 0x00 >;
			ili2672 = < 0x00 >;
			ft5x06 = < 0x00 >;
			MT395 = < 0x00 >;
			NT1100X = < 0x00 >;
			SSD254X = < 0x00 >;
		};
	};

	pcm-audio {
		compatible = "actions,pcm-audio";
		status = "okay";
	};
};
